# CM_CORE_AON__IPU register map
Vendor: Texas Instruments
Peripheral module from a debugger description file (folder DRA74xP_75xP_76xP_77xP).
Registers are 32-bit, access per field, reset 0x30000 unless marked. A register's access mark holds for its fields unless they carry their own. Offsets are as the file gives them; lines under a group give offsets from that group; [hi:lo] are bit positions; {n}, {i} and the like mark numbered series; 'fields as' and 'values as' point back to an identical list; <NAME> marks a mode.

## CM_CORE_AON__IPU
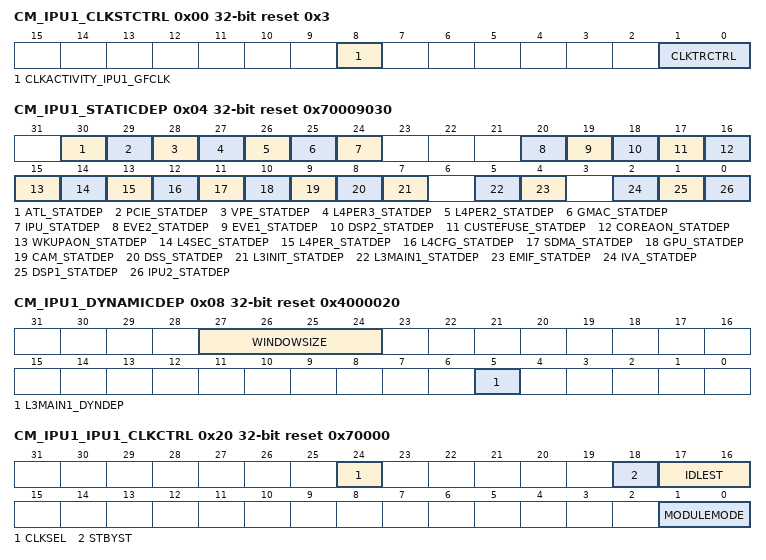
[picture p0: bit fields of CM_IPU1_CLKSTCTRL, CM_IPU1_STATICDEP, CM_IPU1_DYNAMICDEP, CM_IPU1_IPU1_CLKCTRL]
0x00 CM_IPU1_CLKSTCTRL reset 0x3 — This register enables the domain power state transition. It controls the HW supervised domain power state transition between ON-ACTIVE and ON-INACTIVE states. It also hold one status bit per clock input of the domain.
  [8] CLKACTIVITY_IPU1_GFCLK ro — This field indicates the state of the IPU1_GFCLK clock in the domain. [warm reset insensitive]
    0=INACT (Corresponding clock is definitely gated); 1=ACT (Corresponding clock is running or gating/ungating transition is on-going)
  [1:0] CLKTRCTRL rw — Controls the clock state transition of the IPU1 clock domain.
    0=NO_SLEEP (NO_SLEEP: Sleep transition cannot be initiated. Wakeup transition may however occur.); 1=SW_SLEEP (SW_SLEEP: Start a software forced sleep transition on the domain.); 2=SW_WKUP (SW_WKUP: Start a software forced wake-up transition on the domain.); 3=HW_AUTO (HW_AUTO: Automatic transition is enabled. Sleep and wakeup transition are based upon hardware conditions.)
0x04 CM_IPU1_STATICDEP reset 0x70009030 — This register controls the static domain depedencies from IPU domain towards 'target' domains. It is relevant only for domain having system initiator(s).
  [30] ATL_STATDEP rw — Static dependency towards ATL clock domain
    0=DISABLED (Dependency is disabled); 1=ENABLED (Dependency is enabled)
  [29] PCIE_STATDEP rw — Static dependency towards PCIE clock domain
    values as ATL_STATDEP
  [28] VPE_STATDEP rw — Static dependency towards VPE clock domain
    values as ATL_STATDEP
  [27] L4PER3_STATDEP rw — Static dependency towards L4PER3 clock domain
    values as ATL_STATDEP
  [26] L4PER2_STATDEP rw — Static dependency towards L4PER2 clock domain
    values as ATL_STATDEP
  [25] GMAC_STATDEP rw — Static dependency towards GMAC clock domain
    values as ATL_STATDEP
  [24] IPU_STATDEP rw — Static dependency towards IPU clock domain
    values as ATL_STATDEP
  [20] EVE2_STATDEP rw — Static dependency towards EVE2 clock domain
    values as ATL_STATDEP
  [19] EVE1_STATDEP rw — Static dependency towards EVE1 clock domain
    values as ATL_STATDEP
  [18] DSP2_STATDEP rw — Static dependency towards DSP2 clock domain
    values as ATL_STATDEP
  [17] CUSTEFUSE_STATDEP ro — Static dependency towards CUSTEFUSE clock domain
    0=DISABLED (Dependency is disabled)
  [16] COREAON_STATDEP ro — Static dependency towards COREAON clock domain
    0=DISABLED (Dependency is disabled)
  [15] WKUPAON_STATDEP rw — Static dependency towards WKUPAON clock domain
    values as ATL_STATDEP
  [14] L4SEC_STATDEP rw — Static dependency towards L4SEC clock domain
    values as ATL_STATDEP
  [13] L4PER_STATDEP rw — Static dependency towards L4PER1 clock domain
    values as ATL_STATDEP
  [12] L4CFG_STATDEP rw — Static dependency towards L4CFG clock domain
    values as ATL_STATDEP
  [11] SDMA_STATDEP ro — Static dependency towards DMA clock domain
    0=DISABLED (Dependency is disabled)
  [10] GPU_STATDEP rw — Static dependency towards GPU clock domain
    values as ATL_STATDEP
  [9] CAM_STATDEP ro — Static dependency towards CAM clock domain
    0=DISABLED (Dependency is disabled)
  [8] DSS_STATDEP rw — Static dependency towards DSS clock domain
    values as ATL_STATDEP
  [7] L3INIT_STATDEP rw — Static dependency towards L3INIT clock domain
    values as ATL_STATDEP
  [5] L3MAIN1_STATDEP rw — Static dependency towards L3MAIN1 clock domain
    values as ATL_STATDEP
  [4] EMIF_STATDEP rw — Static dependency towards EMIF clock domain
    values as ATL_STATDEP
  [2] IVA_STATDEP rw — Static dependency towards IVA clock domain
    values as ATL_STATDEP
  [1] DSP1_STATDEP rw — Static dependency towards DSP clock domain
    values as ATL_STATDEP
  [0] IPU2_STATDEP rw — Static dependency towards IPU2 clock domain
    values as ATL_STATDEP
0x08 CM_IPU1_DYNAMICDEP reset 0x4000020 — This register controls the dynamic domain depedencies from IPU domain towards 'target' domains. It is relevant only for domain having OCP master port(s).
  [27:24] WINDOWSIZE rw — Size of sliding window used to monitor OCP interface activity for determination of auto-sleep feature. Time unit defined byCM_DYN_DEP_PRESCAL register.
  [5] L3MAIN1_DYNDEP ro — Dynamic dependency towards L3MAIN1 clock domain
    1=ENABLED (Dependency is enabled)
0x20 CM_IPU1_IPU1_CLKCTRL reset 0x70000 — This register manages the IPU1 clocks.
  [24] CLKSEL rw — Selects the timer functional clock
    0=SEL_DPLL_ABE_X2_CLK (Selects DPLL_ABE_X2_CLK as the functional clock); 1=SEL_CORE_IPU_ISS_BOOST_CLK (Selects CORE_IPU_ISS_BOOST_CLK as the functional clock)
  [18] STBYST ro — Module standby status. [warm reset insensitive]
    0=FUNC (Module is functional (not in standby)); 1=STANDBY (Module is in standby)
  [17:16] IDLEST ro — Module idle status. [warm reset insensitive]
    0=FUNC (Module is fully functional, including OCP); 1=TRANS (Module is performing transition: wakeup, or sleep, or sleep abortion); 2=IDLE (Module is in Idle mode (only OCP part). It is functional if using separate functional clock); 3=DISABLE (Module is disabled and cannot be accessed)
  [1:0] MODULEMODE rw — Control the way mandatory clocks are managed.
    0=DISABLED (Module is disabled by SW. Any OCP access to module results in an error, except if resulting from a module wakeup (asynchronous wakeup).); 1=AUTO (Module is managed automatically by HW according to clock domain transition. A clock domain sleep transition put module into idle. A wakeup domain transition put it back into function. If CLKTRCTRL=3, any OCP access to module is always granted. Module clocks may be gated according to the clock domain state.)
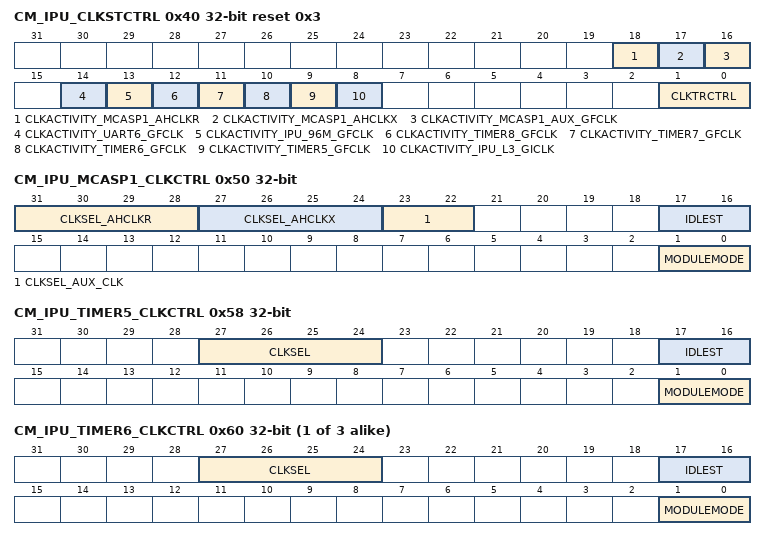
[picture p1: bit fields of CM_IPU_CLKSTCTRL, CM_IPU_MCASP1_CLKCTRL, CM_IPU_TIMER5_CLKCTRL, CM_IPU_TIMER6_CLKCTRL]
0x40 CM_IPU_CLKSTCTRL reset 0x3 — This register enables the ABE domain power state transition. It controls the HW supervised domain power state transition between ON-ACTIVE and ON-INACTIVE states. It also hold one status bit per clock input of the domain.
  [18] CLKACTIVITY_MCASP1_AHCLKR ro — This field indicates the state of the MCASP1_AHCLKR clock in the domain. [warm reset insensitive]
    values as CM_IPU1_CLKSTCTRL.CLKACTIVITY_IPU1_GFCLK
  [17] CLKACTIVITY_MCASP1_AHCLKX ro — This field indicates the state of the MCASP1_AHCLKX clock in the domain. [warm reset insensitive]
    values as CM_IPU1_CLKSTCTRL.CLKACTIVITY_IPU1_GFCLK
  [16] CLKACTIVITY_MCASP1_AUX_GFCLK ro — This field indicates the state of the MCASP1_AUX_GFCLK clock in the domain. [warm reset insensitive]
    values as CM_IPU1_CLKSTCTRL.CLKACTIVITY_IPU1_GFCLK
  [14] CLKACTIVITY_UART6_GFCLK ro — This field indicates the state of the UART6_GFCLK clock in the domain. [warm reset insensitive]
    values as CM_IPU1_CLKSTCTRL.CLKACTIVITY_IPU1_GFCLK
  [13] CLKACTIVITY_IPU_96M_GFCLK ro — This field indicates the state of the IPU_96M_GFCLK clock in the domain. [warm reset insensitive]
    values as CM_IPU1_CLKSTCTRL.CLKACTIVITY_IPU1_GFCLK
  [12] CLKACTIVITY_TIMER8_GFCLK ro — This field indicates the state of the TIMER8_GFCLK clock in the domain. [warm reset insensitive]
    values as CM_IPU1_CLKSTCTRL.CLKACTIVITY_IPU1_GFCLK
  [11] CLKACTIVITY_TIMER7_GFCLK ro — This field indicates the state of the TIMER7_GFCLK clock in the domain. [warm reset insensitive]
    values as CM_IPU1_CLKSTCTRL.CLKACTIVITY_IPU1_GFCLK
  [10] CLKACTIVITY_TIMER6_GFCLK ro — This field indicates the state of the TIMER6_GFCLK clock in the domain. [warm reset insensitive]
    values as CM_IPU1_CLKSTCTRL.CLKACTIVITY_IPU1_GFCLK
  [9] CLKACTIVITY_TIMER5_GFCLK ro — This field indicates the state of the TIMER5_GFCLK functional clock in the domain. [warm reset insensitive]
    values as CM_IPU1_CLKSTCTRL.CLKACTIVITY_IPU1_GFCLK
  [8] CLKACTIVITY_IPU_L3_GICLK ro — This field indicates the state of the IPU_L3_GICLK interface clock in the domain. [warm reset insensitive]
    values as CM_IPU1_CLKSTCTRL.CLKACTIVITY_IPU1_GFCLK
  [1:0] CLKTRCTRL rw — Controls the clock state transition of the ABE clock domain.
    values as CM_IPU1_CLKSTCTRL.CLKTRCTRL
0x50 CM_IPU_MCASP1_CLKCTRL — This register manages the McASP clocks.
  [31:28] CLKSEL_AHCLKR rw — Selects reference clock for AHCLKR
    0=SEL_ABE_24M_GFCLK (Selects ABE_24M_GFCLK); 1=SEL_ABE_SYS_CLK (Selects ABE_SYS_CLK); 2=SEL_FUNC_24M_GFCLK (Selects FUNC_24M_GFCLK); 3=SEL_ATL_CLK3 (Selects ATL CLK3); 4=SEL_ATL_CLK2 (Selects ATL CLK2); 5=SEL_ATL_CLK1 (Selects ATL CLK1); 6=SEL_ATL_CLK0 (Selects ATL CLK0); 7=SEL_SYS_SLK2 (Selects SYS_CLK2); {v}=SEL_XREF_CLK{v-8} (Selects XREF_CLK{v-8}) (v=8..11); 12=SEL_MLB_CLK (Selects MLB_CLK); 13=SEL_MLBP_CLK (Selects MLBP_CLK)
  [27:24] CLKSEL_AHCLKX rw — Selects reference clock for AHCLKX
    values as CLKSEL_AHCLKR
  [23:22] CLKSEL_AUX_CLK rw — Selects the source of the AUX clock
    0=SEL_PER_ABE_X1_GFCLK (Selects PER_ABE_X1_GFCLK); 1=SEL_VIDEO1_CLK (Selects VIDEO1 CLK); 2=SEL_VIDEO2_CLK (Selects VIDEO2 CLK); 3=SEL_HDMI_CLK (Selects HDMI CLK)
  [17:16] IDLEST ro — Module idle status. [warm reset insensitive]
    values as CM_IPU1_IPU1_CLKCTRL.IDLEST
  [1:0] MODULEMODE rw — Control the way mandatory clocks are managed.
    0=DISABLED (Module is disabled by SW. Any OCP access to module results in an error, except if resulting from a module wakeup (asynchronous wakeup).); 2=ENABLE (Module is explicitly enabled. Interface clock (if not used for functions) may be gated according to the clock domain state. Functional clocks are guarantied to stay present. As long as in this configuration, power domain sleep transition cannot happen.)
0x58 CM_IPU_TIMER5_CLKCTRL — This register manages the TIMER5 clocks.
  [27:24] CLKSEL rw — Selects the timer functional clock0xC-0xF: RESERVED enum=RESERVED .
    0=SEL_TIMER_SYS_CLK (Selects TIMER_SYS_CLK); 1=SEL_SYS_CLK1_32K_CLK (Selects FUNC_32K_CLK); 2=SEL_SYS_CLK2 (Selects SYS_CLK2); {v}=SEL_XREF_CLK{v-3} (Selects XREF_CLK{v-3}) (v=3..6); 7=SEL_ABE_GICLK (Selects ABE_GICLK); 8=SEL_VIDEO1_CLK (Selects VIDEO1_DIV_CLK); 9=SEL_VIDEO2_CLK (Selects VIDEO2_DIV_CLK); 10=SEL_HDMI_CLK (Selects HDMI_DIV_CLK); 11=SEL_CLKOUTMUX_CLK (Selects CLKOUTMUX0_CLK)
  [17:16] IDLEST ro — Module idle status. [warm reset insensitive]
    values as CM_IPU1_IPU1_CLKCTRL.IDLEST
  [1:0] MODULEMODE rw — Control the way mandatory clocks are managed.
    values as CM_IPU_MCASP1_CLKCTRL.MODULEMODE
{0x30+8i} CM_IPU_TIMER{i}_CLKCTRL (i=6..8) — This register manages the TIMER{i} clocks.
  [27:24] CLKSEL rw — Selects the timer functional clock0xC-0xF: RESERVED enum=RESERVED .
    0=SEL_TIMER_SYS_CLK (Selects TIMER_SYS_CLK); 1=SEL_SYS_CLK1_32K_CLK (Selects FUNC_32K_CLK); 2=SEL_SYS_CLK2 (Selects SYS_CLK2); {v}=SEL_XREF_CLK{v-3} (Selects XREF_CLK{v-3}) (v=3..6); 7=SEL_ABE_GICLK (Selects ABE_GICLK); 8=SEL_VIDEO1_CLK (Selects VIDEO1_DIV_CLK); 9=SEL_VIDEO2_CLK (Selects VIDEO2_DIV_CLK); 10=SEL_HDMI_CLK (Selects HDMI_DIV _CLK); 11=SEL_CLKOUTMUX_CLK (Selects CLKOUTMUX0_CLK)
  [17:16] IDLEST ro — Module idle status. [warm reset insensitive]
    values as CM_IPU1_IPU1_CLKCTRL.IDLEST
  [1:0] MODULEMODE rw — Control the way mandatory clocks are managed.
    values as CM_IPU_MCASP1_CLKCTRL.MODULEMODE
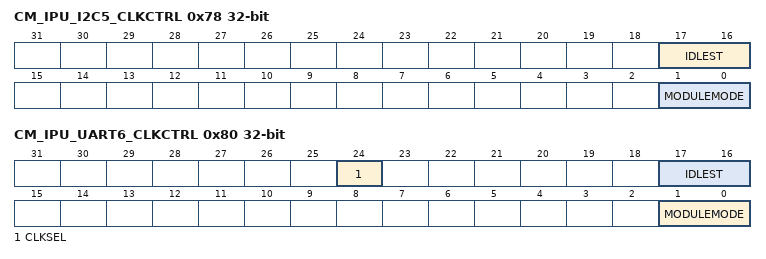
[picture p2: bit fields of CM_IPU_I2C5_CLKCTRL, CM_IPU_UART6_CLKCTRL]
0x78 CM_IPU_I2C5_CLKCTRL — This register manages the I2C5 clocks.
  [17:16] IDLEST ro — Module idle status. [warm reset insensitive]
    values as CM_IPU1_IPU1_CLKCTRL.IDLEST
  [1:0] MODULEMODE rw — Control the way mandatory clocks are managed.
    values as CM_IPU_MCASP1_CLKCTRL.MODULEMODE
0x80 CM_IPU_UART6_CLKCTRL — This register manages the UART6 clocks.
  [24] CLKSEL rw — Selects functional clock for UART between FUNC_48M_FCLK and FUNC_192M_CLK
    0=SEL_FUNC_48M_CLK (Selects FUNC_48M_FCLK); 1=SEL_FUNC_192M_CLK (Selects FUNC_192M_CLK)
  [17:16] IDLEST ro — Module idle status. [warm reset insensitive]
    values as CM_IPU1_IPU1_CLKCTRL.IDLEST
  [1:0] MODULEMODE rw — Control the way mandatory clocks are managed.
    values as CM_IPU_MCASP1_CLKCTRL.MODULEMODE
